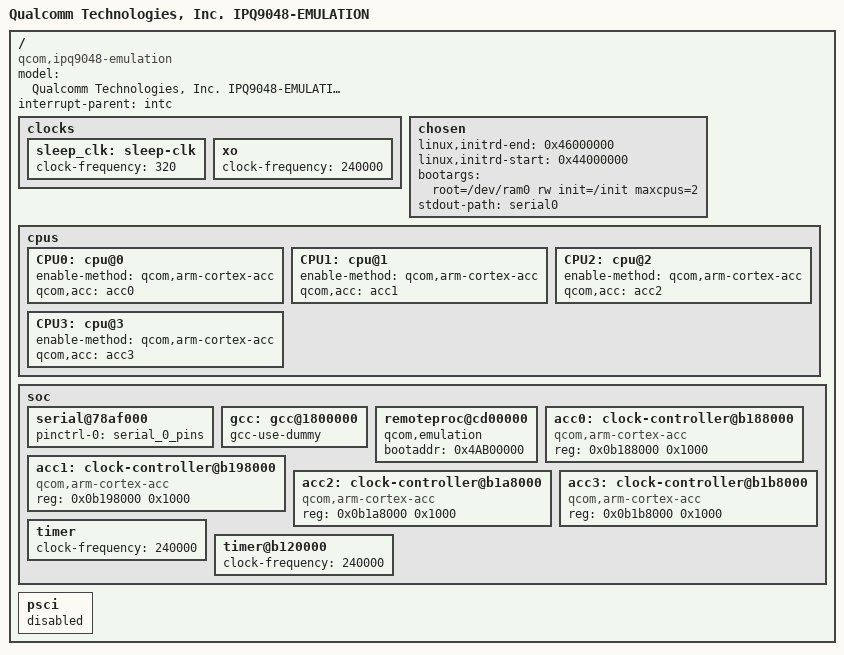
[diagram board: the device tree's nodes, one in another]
// SPDX-License-Identifier: (GPL-2.0+ OR BSD-3-Clause)
/*
 * IPQ9048 Emulation board device tree source
 *
 * Copyright (c) 2020-2021 The Linux Foundation. All rights reserved.
 */

/dts-v1/;

#include "ipq9048.dtsi"

/ {
	#address-cells = <0x2>;
	#size-cells = <0x2>;
	model = "Qualcomm Technologies, Inc. IPQ9048-EMULATION";
	compatible = "qcom,ipq9048-emulation", "qcom,ipq9048";
	interrupt-parent = <&intc>;

	clocks {
		sleep_clk: sleep-clk {
			clock-frequency = <320>;
		};

		xo: xo {
			clock-frequency = <240000>;
		};
	};

	chosen {
		linux,initrd-end = <0x46000000>;
		linux,initrd-start = <0x44000000>;
		bootargs = "root=/dev/ram0 rw init=/init maxcpus=2";
		stdout-path = "serial0";
	};

	cpus: cpus {
		CPU0: cpu@0 {
			enable-method = "qcom,arm-cortex-acc";
			qcom,acc = <&acc0>;
		};

		CPU1: cpu@1 {
			enable-method = "qcom,arm-cortex-acc";
			qcom,acc = <&acc1>;
		};

		CPU2: cpu@2 {
			enable-method = "qcom,arm-cortex-acc";
			qcom,acc = <&acc2>;
		};

		CPU3: cpu@3 {
			enable-method = "qcom,arm-cortex-acc";
			qcom,acc = <&acc3>;
		};
	};

	soc {
		serial@78af000 {
			pinctrl-0 = <&serial_0_pins>;
			pinctrl-names = "default";
			status = "ok";
		};

		gcc: gcc@1800000 {
			gcc-use-dummy;
		};

		remoteproc@cd00000 {
			qcom,emulation;
			bootaddr = <0x4AB00000>;
		};

		acc0: clock-controller@b188000 {
			compatible = "qcom,arm-cortex-acc";
			reg = <0x0b188000 0x1000>;
		};

		acc1: clock-controller@b198000 {
			compatible = "qcom,arm-cortex-acc";
			reg = <0x0b198000 0x1000>;
		};

		acc2:clock-controller@b1a8000 {
			compatible = "qcom,arm-cortex-acc";
			reg = <0x0b1a8000 0x1000>;
		};

		acc3:clock-controller@b1b8000 {
			compatible = "qcom,arm-cortex-acc";
			reg = <0x0b1b8000 0x1000>;
		};

		/*Timer freq for rumi = timer freq / 100*/
		timer {
			clock-frequency = <240000>;
		};

		timer@b120000 {
			clock-frequency = <240000>;
		};

	};

	psci {
		status = "disabled";
	};
};
